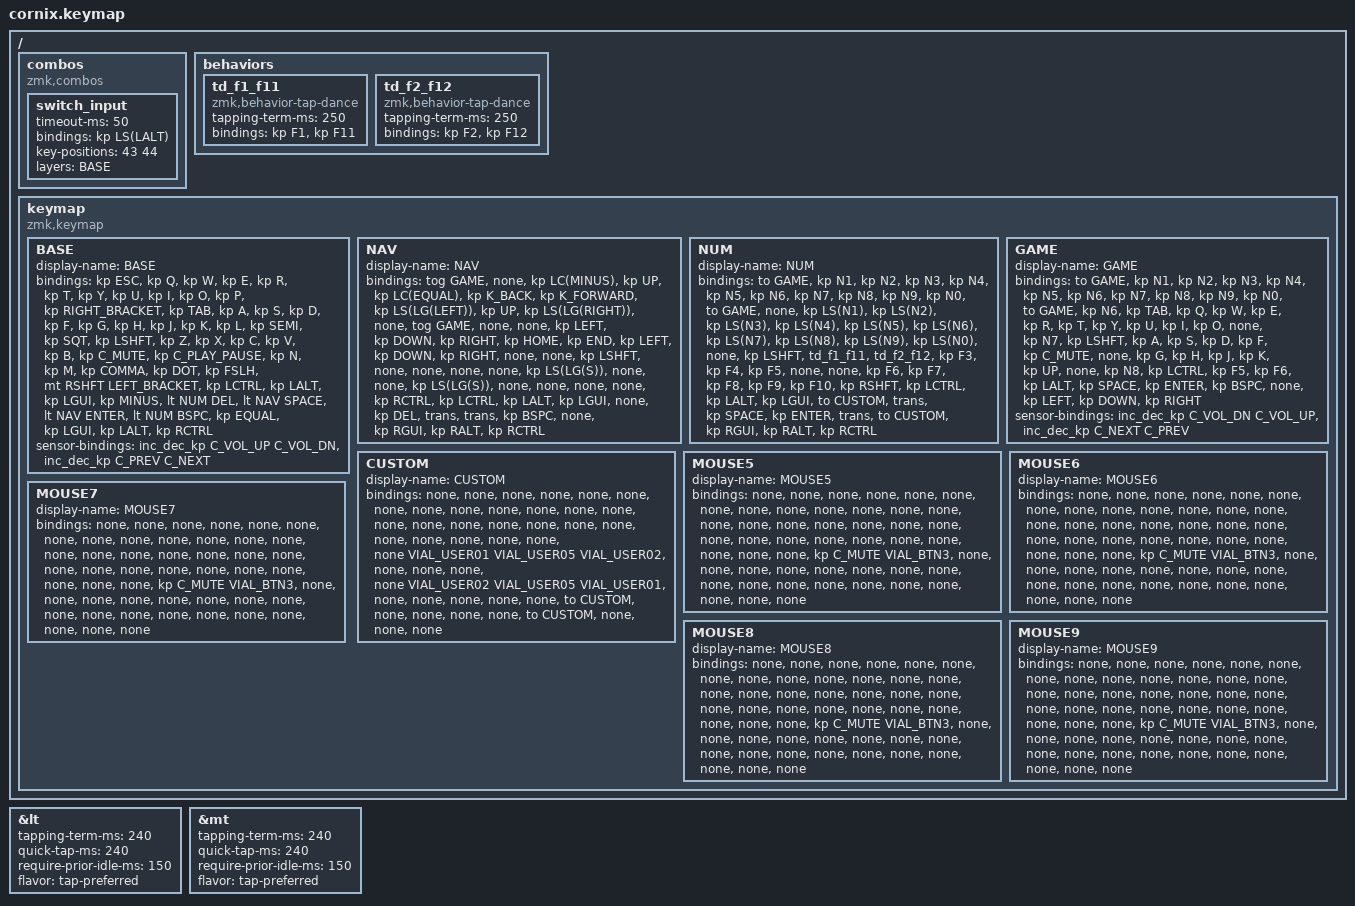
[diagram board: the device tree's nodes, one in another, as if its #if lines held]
/*
 * Cornix keymap migrated from cornix_17.vil.
 *
 * Migrated from Vial:
 *   - all 10 keymap layers
 *   - combo: LT1(SPACE) + LT1(ENTER) -> Left Shift + Left Alt
 *   - tap dances: F1/F11 and F2/F12, 250 ms
 *   - QMK/Vial tap-hold timing: TAPPING_TERM 240 ms, FLOW_TAP 150 ms
 *
 * USER01/USER02/USER05 are Vial custom keycodes. Their implementation is not
 * contained in the .vil file, so their positions are preserved through
 * VIAL_USERxx placeholders, which default to &none below.
 *
 * SPDX-License-Identifier: MIT
 */

#include "zmk-helpers/helper.h"
#include "includes/cornix54.h"

#include <behaviors.dtsi>
#include <dt-bindings/zmk/keys.h>
#include <dt-bindings/zmk/pointing.h>

#define BASE    0
#define NAV     1
#define NUM     2
#define GAME    3
#define CUSTOM  4
#define MOUSE5  5
#define MOUSE6  6
#define MOUSE7  7
#define MOUSE8  8
#define MOUSE9  9

/*
 * Vial/QMK tap-hold settings:
 *   TAPPING_TERM = 240 ms
 *   FLOW_TAP     = 150 ms
 *
 * QMK's default tap/hold decision ignores interruptions. "tap-preferred" is
 * the closest ZMK flavor. QMK QUICK_TAP_TERM defaults to TAPPING_TERM when no
 * override is stored, so quick-tap-ms is also 240 ms.
 */
&lt {
    tapping-term-ms = <240>;
    quick-tap-ms = <240>;
    require-prior-idle-ms = <150>;
    flavor = "tap-preferred";
};

&mt {
    tapping-term-ms = <240>;
    quick-tap-ms = <240>;
    require-prior-idle-ms = <150>;
    flavor = "tap-preferred";
};

/* KC_BTN3 from the Vial layers. */
#ifdef CONFIG_ZMK_POINTING
#define VIAL_BTN3 &mkp MB3
#else
#define VIAL_BTN3 &none
#endif

/*
 * The .vil file stores only USER01/USER02/USER05 identifiers, not the code
 * behind them. Replace these with the corresponding ZMK behaviors when their
 * original custom-keycode implementation is available.
 */
#ifndef VIAL_USER01
#define VIAL_USER01 &none
#endif
#ifndef VIAL_USER02
#define VIAL_USER02 &none
#endif
#ifndef VIAL_USER05
#define VIAL_USER05 &none
#endif

/ {
    combos {
        compatible = "zmk,combos";

        switch_input {
            timeout-ms = <50>;
            bindings = <&kp LS(LALT)>;
            key-positions = <43 44>;
            layers = <BASE>;
        };
    };

    behaviors {
        td_f1_f11: td_f1_f11 {
            compatible = "zmk,behavior-tap-dance";
            #binding-cells = <0>;
            tapping-term-ms = <250>;
            bindings = <&kp F1>, <&kp F11>;
        };

        td_f2_f12: td_f2_f12 {
            compatible = "zmk,behavior-tap-dance";
            #binding-cells = <0>;
            tapping-term-ms = <250>;
            bindings = <&kp F2>, <&kp F12>;
        };
    };

    keymap {
        compatible = "zmk,keymap";

        BASE {
            display-name = "BASE";
            bindings = <
                &kp ESC  &kp Q  &kp W  &kp E  &kp R  &kp T  &kp Y  &kp U  &kp I  &kp O  &kp P  &kp RIGHT_BRACKET
                &kp TAB  &kp A  &kp S  &kp D  &kp F  &kp G  &kp H  &kp J  &kp K  &kp L  &kp SEMI  &kp SQT
                &kp LSHFT  &kp Z  &kp X  &kp C  &kp V  &kp B  &kp C_MUTE  &kp C_PLAY_PAUSE  &kp N  &kp M  &kp COMMA  &kp DOT  &kp FSLH  &mt RSHFT LEFT_BRACKET
                &kp LCTRL  &kp LALT  &kp LGUI  &kp MINUS  &lt NUM DEL  &lt NAV SPACE  &lt NAV ENTER  &lt NUM BSPC  &kp EQUAL  &kp LGUI  &kp LALT  &kp RCTRL
            >;
            sensor-bindings = <&inc_dec_kp C_VOL_UP C_VOL_DN &inc_dec_kp C_PREV C_NEXT>;
        };

        NAV {
            display-name = "NAV";
            bindings = <
                &tog GAME  &none  &kp LC(MINUS)  &kp UP  &kp LC(EQUAL)  &kp K_BACK  &kp K_FORWARD  &kp LS(LG(LEFT))  &kp UP  &kp LS(LG(RIGHT))  &none  &tog GAME
                &none  &none  &kp LEFT  &kp DOWN  &kp RIGHT  &kp HOME  &kp END  &kp LEFT  &kp DOWN  &kp RIGHT  &none  &none
                &kp LSHFT  &none  &none  &none  &none  &kp LS(LG(S))  &none  &none  &kp LS(LG(S))  &none  &none  &none  &none  &kp RCTRL
                &kp LCTRL  &kp LALT  &kp LGUI  &none  &kp DEL  &trans  &trans  &kp BSPC  &none  &kp RGUI  &kp RALT  &kp RCTRL
            >;
        };

        NUM {
            display-name = "NUM";
            bindings = <
                &to GAME  &kp N1  &kp N2  &kp N3  &kp N4  &kp N5  &kp N6  &kp N7  &kp N8  &kp N9  &kp N0  &to GAME
                &none  &kp LS(N1)  &kp LS(N2)  &kp LS(N3)  &kp LS(N4)  &kp LS(N5)  &kp LS(N6)  &kp LS(N7)  &kp LS(N8)  &kp LS(N9)  &kp LS(N0)  &none
                &kp LSHFT  &td_f1_f11  &td_f2_f12  &kp F3  &kp F4  &kp F5  &none  &none  &kp F6  &kp F7  &kp F8  &kp F9  &kp F10  &kp RSHFT
                &kp LCTRL  &kp LALT  &kp LGUI  &to CUSTOM  &trans  &kp SPACE  &kp ENTER  &trans  &to CUSTOM  &kp RGUI  &kp RALT  &kp RCTRL
            >;
        };

        GAME {
            display-name = "GAME";
            bindings = <
                &to GAME  &kp N1  &kp N2  &kp N3  &kp N4  &kp N5  &kp N6  &kp N7  &kp N8  &kp N9  &kp N0  &to GAME
                &kp N6  &kp TAB  &kp Q  &kp W  &kp E  &kp R  &kp T  &kp Y  &kp U  &kp I  &kp O  &none
                &kp N7  &kp LSHFT  &kp A  &kp S  &kp D  &kp F  &kp C_MUTE  &none  &kp G  &kp H  &kp J  &kp K  &kp UP  &none
                &kp N8  &kp LCTRL  &kp F5  &kp F6  &kp LALT  &kp SPACE  &kp ENTER  &kp BSPC  &none  &kp LEFT  &kp DOWN  &kp RIGHT
            >;
            sensor-bindings = <&inc_dec_kp C_VOL_DN C_VOL_UP &inc_dec_kp C_NEXT C_PREV>;
        };

        CUSTOM {
            display-name = "CUSTOM";
            bindings = <
                &none  &none  &none  &none  &none  &none  &none  &none  &none  &none  &none  &none
                &none  &none  &none  &none  &none  &none  &none  &none  &none  &none  &none  &none
                &none  &none  VIAL_USER01  VIAL_USER05  VIAL_USER02  &none  &none  &none  &none  VIAL_USER02  VIAL_USER05  VIAL_USER01  &none  &none
                &none  &none  &none  &to CUSTOM  &none  &none  &none  &none  &to CUSTOM  &none  &none  &none
            >;
        };

        MOUSE5 {
            display-name = "MOUSE5";
            bindings = <
                &none  &none  &none  &none  &none  &none  &none  &none  &none  &none  &none  &none
                &none  &none  &none  &none  &none  &none  &none  &none  &none  &none  &none  &none
                &none  &none  &none  &none  &none  &none  &kp C_MUTE  VIAL_BTN3  &none  &none  &none  &none  &none  &none
                &none  &none  &none  &none  &none  &none  &none  &none  &none  &none  &none  &none
            >;
        };

        MOUSE6 {
            display-name = "MOUSE6";
            bindings = <
                &none  &none  &none  &none  &none  &none  &none  &none  &none  &none  &none  &none
                &none  &none  &none  &none  &none  &none  &none  &none  &none  &none  &none  &none
                &none  &none  &none  &none  &none  &none  &kp C_MUTE  VIAL_BTN3  &none  &none  &none  &none  &none  &none
                &none  &none  &none  &none  &none  &none  &none  &none  &none  &none  &none  &none
            >;
        };

        MOUSE7 {
            display-name = "MOUSE7";
            bindings = <
                &none  &none  &none  &none  &none  &none  &none  &none  &none  &none  &none  &none
                &none  &none  &none  &none  &none  &none  &none  &none  &none  &none  &none  &none
                &none  &none  &none  &none  &none  &none  &kp C_MUTE  VIAL_BTN3  &none  &none  &none  &none  &none  &none
                &none  &none  &none  &none  &none  &none  &none  &none  &none  &none  &none  &none
            >;
        };

        MOUSE8 {
            display-name = "MOUSE8";
            bindings = <
                &none  &none  &none  &none  &none  &none  &none  &none  &none  &none  &none  &none
                &none  &none  &none  &none  &none  &none  &none  &none  &none  &none  &none  &none
                &none  &none  &none  &none  &none  &none  &kp C_MUTE  VIAL_BTN3  &none  &none  &none  &none  &none  &none
                &none  &none  &none  &none  &none  &none  &none  &none  &none  &none  &none  &none
            >;
        };

        MOUSE9 {
            display-name = "MOUSE9";
            bindings = <
                &none  &none  &none  &none  &none  &none  &none  &none  &none  &none  &none  &none
                &none  &none  &none  &none  &none  &none  &none  &none  &none  &none  &none  &none
                &none  &none  &none  &none  &none  &none  &kp C_MUTE  VIAL_BTN3  &none  &none  &none  &none  &none  &none
                &none  &none  &none  &none  &none  &none  &none  &none  &none  &none  &none  &none
            >;
        };
    };
};
